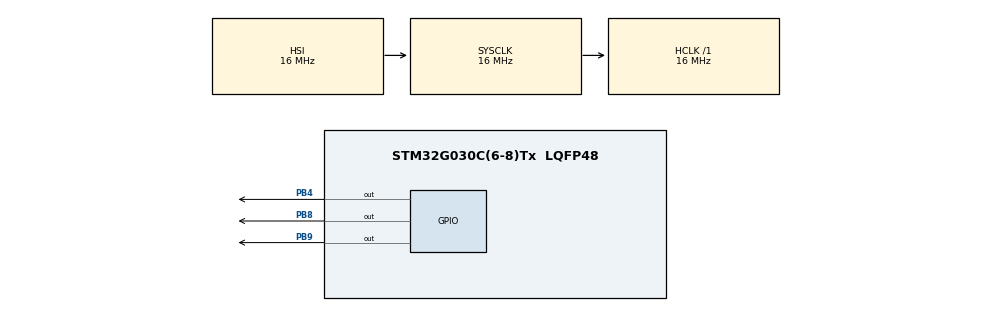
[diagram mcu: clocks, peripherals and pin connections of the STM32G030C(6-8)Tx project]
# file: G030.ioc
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Mcu.Family=STM32G0
Mcu.Name=STM32G030C(6-8)Tx
Mcu.Package=LQFP48
PA13.Mode=Serial_Wire
PA13.Signal=SYS_SWDIO
PA14-BOOT0.Mode=Serial_Wire
PA14-BOOT0.Signal=SYS_SWCLK
PB4.Signal=GPIO_Output
PB8.Signal=GPIO_Output
PB9.Signal=GPIO_Output
ProjectManager.HeapSize=0x200
ProjectManager.StackSize=0x400
ProjectManager.TargetToolchain=MDK-ARM V5.32
RCC.ADCFreq_Value=16000000
RCC.AHBFreq_Value=16000000
RCC.CortexFreq_Value=16000000
RCC.EXTERNAL_CLOCK_VALUE=12288000
RCC.HCLKFreq_Value=16000000
RCC.HSE_VALUE=8000000
RCC.HSI_VALUE=16000000
RCC.LSE_VALUE=32768
RCC.SYSCLKFreq_VALUE=16000000
RCC.VCOOutputFreq_Value=128000000
board=custom

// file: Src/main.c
/* USER CODE BEGIN Header */
/**
  ******************************************************************************
  * @file           : main.c
  * @brief          : Main program body
  ******************************************************************************
  * @attention
  *
  * <h2><center>&copy; Copyright (c) 2020 STMicroelectronics.
  * All rights reserved.</center></h2>
  *
  * This software component is licensed by ST under BSD 3-Clause license,
  * the "License"; You may not use this file except in compliance with the
  * License. You may obtain a copy of the License at:
  *                        opensource.org/licenses/BSD-3-Clause
  *
  ******************************************************************************
  */
/* USER CODE END Header */

#include "main.h"
#include "gpio.h"

/* USER CODE BEGIN Includes */
#include "oled.h"
#include "bmp.h"
/* USER CODE END Includes */

void SystemClock_Config(void);

int main(void)
{
  /* USER CODE BEGIN 1 */
	unsigned char t;
  /* USER CODE END 1 */

  /* MCU Configuration--------------------------------------------------------*/

  /* Reset of all peripherals, Initializes the Flash interface and the Systick. */
  HAL_Init();

  /* Configure the system clock */
  SystemClock_Config();

  /* Initialize all configured peripherals */
  MX_GPIO_Init();
  /* USER CODE BEGIN 2 */
  OLED_Init();			       //初始化OLED
  OLED_Clear()  	;
  t=' ';
  /* USER CODE END 2 */

  /* Infinite loop */
  while (1)
  {

    /* USER CODE BEGIN 3 */
    OLED_Clear();
    OLED_ShowCHinese(18,0,0);
    OLED_ShowCHinese(36,0,1);
    OLED_ShowCHinese(54,0,2);
    OLED_ShowCHinese(72,0,3);
    OLED_ShowCHinese(90,0,4);

    OLED_ShowString(6,3,"0.96' OLED TEST",16);
    OLED_ShowString(0,6,"ASCII:",16);
    OLED_ShowString(63,6,"CODE:",16);
    OLED_ShowChar(48,6,t,16);//显示ASCII字符
    t++;
    if(t>'~')t=' ';
    OLED_ShowNum(103,6,t,3,16);//显示ASCII字符的码
    HAL_Delay(2000);
    HAL_GPIO_TogglePin(GPIOB, GPIO_PIN_4);
    OLED_DrawBMP(0,0,128,8,BMP5);
    HAL_Delay(2000);
    HAL_GPIO_TogglePin(GPIOB, GPIO_PIN_4);
  }
  /* USER CODE END 3 */
}

void SystemClock_Config(void)
{
  RCC_OscInitTypeDef RCC_OscInitStruct = {0};
  RCC_ClkInitTypeDef RCC_ClkInitStruct = {0};

  /** Configure the main internal regulator output voltage
  */
  HAL_PWREx_ControlVoltageScaling(PWR_REGULATOR_VOLTAGE_SCALE1);
  /** Initializes the CPU, AHB and APB busses clocks
  */
  RCC_OscInitStruct.OscillatorType = RCC_OSCILLATORTYPE_HSI;
  RCC_OscInitStruct.HSIState = RCC_HSI_ON;
  RCC_OscInitStruct.HSIDiv = RCC_HSI_DIV1;
  RCC_OscInitStruct.HSICalibrationValue = RCC_HSICALIBRATION_DEFAULT;
  RCC_OscInitStruct.PLL.PLLState = RCC_PLL_NONE;
  if (HAL_RCC_OscConfig(&RCC_OscInitStruct) != HAL_OK)
  {
    Error_Handler();
  }
  /** Initializes the CPU, AHB and APB busses clocks
  */
  RCC_ClkInitStruct.ClockType = RCC_CLOCKTYPE_HCLK|RCC_CLOCKTYPE_SYSCLK
                              |RCC_CLOCKTYPE_PCLK1;
  RCC_ClkInitStruct.SYSCLKSource = RCC_SYSCLKSOURCE_HSI;
  RCC_ClkInitStruct.AHBCLKDivider = RCC_SYSCLK_DIV1;
  RCC_ClkInitStruct.APB1CLKDivider = RCC_HCLK_DIV1;

  if (HAL_RCC_ClockConfig(&RCC_ClkInitStruct, FLASH_LATENCY_0) != HAL_OK)
  {
    Error_Handler();
  }
}

void Error_Handler(void)
{
}

/************************ (C) COPYRIGHT STMicroelectronics *****END OF FILE****/
